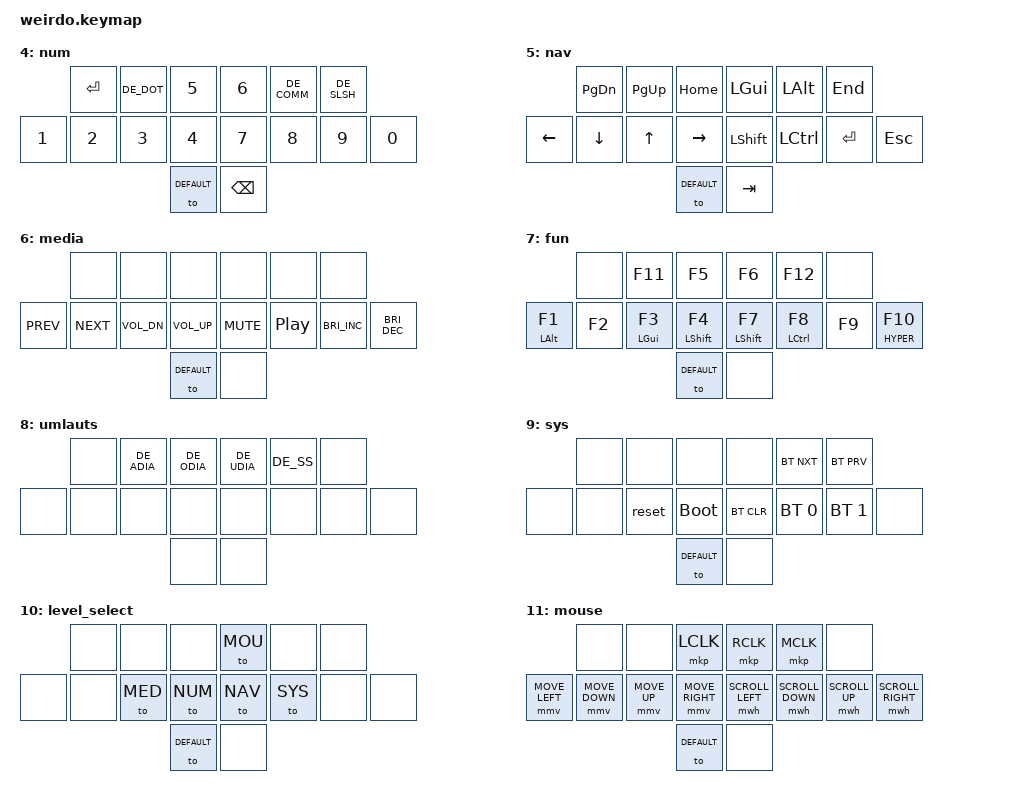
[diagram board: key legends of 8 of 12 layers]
/*
 * Copyright (c) 2021 The ZMK Contributors
 *
 * SPDX-License-Identifier: MIT
 */

#include <behaviors.dtsi>
#include <dt-bindings/zmk/keys.h>
#include <dt-bindings/zmk/bt.h>
#include <dt-bindings/zmk/ext_power.h>
#include <dt-bindings/zmk/mouse.h>

/* GERMAN KEY CODES */
#define DE_CIRC GRAVE // ^ (dead)
#define DE_SS   MINUS // ß
#define DE_ACUT EQUAL // ´ (dead)
#define DE_Q    Q            // Q
#define DE_W    W            // W
#define DE_E    E            // E
#define DE_R    R            // R
#define DE_T    T            // T
#define DE_Z    Y            // Z
#define DE_U    U            // U
#define DE_I    I            // I
#define DE_O    O            // O
#define DE_P    P            // P
#define DE_UDIA LEFT_BRACKET // Ü
#define DE_PLUS RIGHT_BRACKET // +
#define DE_A    A            // A
#define DE_S    S            // S
#define DE_D    D            // D
#define DE_F    F            // F
#define DE_G    G            // G
#define DE_H    H            // H
#define DE_J    J            // J
#define DE_K    K            // K
#define DE_L    L            // L
#define DE_ODIA SEMICOLON    // Ö
#define DE_ADIA SINGLE_QUOTE // Ä
#define DE_HASH NON_US_HASH  // #
#define DE_LABK NON_US_BACKSLASH // <
#define DE_Y    Z                // Y
#define DE_X    X                // X
#define DE_C    C                // C
#define DE_V    V                // V
#define DE_B    B                // B
#define DE_N    N                // N
#define DE_M    M                // M
#define DE_COMM COMMA            // ,
#define DE_DOT  PERIOD           // .
#define DE_MINS SLASH            // -
#define DE_DEG  LS(DE_CIRC) // °
#define DE_EXLM LS(NUMBER_1)    // !
#define DE_DQUO LS(NUMBER_2)    // "
#define DE_SECT LS(NUMBER_3)    // §
#define DE_DLR  LS(NUMBER_4)    // $
#define DE_PERC LS(NUMBER_5)    // %
#define DE_AMPR LS(NUMBER_6)    // &
#define DE_SLSH LS(NUMBER_7)    // /
#define DE_LPRN LS(NUMBER_8)    // (
#define DE_RPRN LS(NUMBER_9)    // )
#define DE_EQL  LS(NUMBER_0)    // =
#define DE_QUES LS(DE_SS)   // ?
#define DE_GRV  LS(DE_ACUT) // ` (dead)
#define DE_ASTR LS(DE_PLUS) // *
#define DE_QUOT LS(DE_HASH) // '
#define DE_RABK LS(DE_LABK) // >
#define DE_SCLN LS(DE_COMM) // ;
#define DE_COLN LS(DE_DOT)  // :
#define DE_UNDS LS(DE_MINS) // _
#define DE_LBRC LA(NUMBER_5)    // [
#define DE_RBRC LA(NUMBER_6)    // ]
#define DE_PIPE LA(NUMBER_7)    // |
#define DE_LCBR LA(NUMBER_8)    // {
#define DE_RCBR LA(NUMBER_9)    // }
#define DE_AT LA(DE_L)    // @
#define DE_EURO LA(DE_E)    // €
#define DE_TILD LA(DE_N)    // ~
#define DE_BSLS LS(LA(NUMBER_7))    // (backslash)

#define DEFAULT 0
#define ALPHA_1 DEFAULT
#define ALPHA_2 1
#define SY1 2
#define SY2 3
#define NUM 4
#define NAV 5
#define MED 6
#define FUN 7
#define UML 8
#define SYS 9
#define LVL 10
#define MOU 11
                                     
#define HOLD_TAP_TIME 200
#define _____ &none
#define HYPER LC(LG(LS(LALT)))

/ {
    conditional_layers {
        compatible = "zmk,conditional-layers";
        tri_layer {
            if-layers = <SY1 SY2>;
            then-layer = <LVL>;
        };
    };
};

&mt {
  tapping-term-ms = <HOLD_TAP_TIME>;
  flavor = "tap-preferred";
  quick_tap_ms = <50>;
};

&lt {
  tapping-term-ms = <HOLD_TAP_TIME>;
  quick_tap_ms = <0>;
  flavor = "tap-preferred";
};

#define DEFAULT_LAYER( K1,  K2,  K3,  K4,  K5,  K6,  K7,  K8, K9,  K10, K11, K12, K13, K14, K15, K16 ) \
                &lt UML K1  &lt NUM K2  &lt NAV K3    &lt NAV K4    &lt NUM K5    &lt UML K6 \
  &hk LALT K7   &lt SY1 K8  &hk LGUI K9 &hk LSHFT K10 &hk LSHFT K11 &hk LCTRL K12 &lt SY2 K13 &hk HYPER K14 \
                                                                K15 K16

/ {
  behaviors {
    hk: hk {
      compatible = "zmk,behavior-hold-tap";
      label = "hk";
      #binding-cells = <2>;
      flavor = "tap-preferred";
      tapping-term-ms = <HOLD_TAP_TIME>;
      quick-tap-ms = <50>;
      bindings = <&sk>, <&kp>;
    };
  };

  keymap {
    compatible = "zmk,keymap";

    // This is a sample keymap intended to be replaced with your own
    alpha_1 {
      bindings = <
        DEFAULT_LAYER(
                DE_L, DE_U, DE_A,       DE_B, DE_D, DE_G, 
          DE_C, DE_R, DE_I, DE_E,       DE_N, DE_T, DE_S, DE_H,
                            &kp SPACE,  &mo ALPHA_2
        )
      >;
    };

    alpha_2 {
      bindings = <
        DEFAULT_LAYER(
                DE_DOT, DE_COMM,  DE_J,          DE_W, DE_Y, DE_Q, 
          DE_V, DE_X,   DE_Z,     DE_O,          DE_M, DE_P, DE_F, DE_K,
                                  &kp BACKSPACE, _____
        )
      >;
    };

    sym_1 {
            bindings = <
                DEFAULT_LAYER(
                    DE_LABK, DE_LBRC, DE_LCBR,      DE_LPRN,     DE_RPRN, DE_RCBR, DE_RBRC, DE_RABK, 
                              DE_SCLN, DE_DQUO,     DE_QUOT,     DE_EXLM, DE_QUES, DE_COLN,     
                                                 &kp DE_DLR, &kp DE_MINS
                )
            >;
        };

    sym_2 {
      bindings = <
           DEFAULT_LAYER(
                             DE_TILD, DE_PIPE,     DE_HASH,     DE_ACUT, DE_DEG,  DE_CIRC,
                    DE_EURO, DE_BSLS, DE_SLSH,     DE_ASTR,     DE_PERC, DE_AMPR, DE_EQL,  DE_GRV, 
                                               &kp DE_UNDS, &kp DE_PLUS           
                )
        >;
    };

    num {
      bindings = <
                &kp ENTER &kp DE_DOT  &kp N5      &kp N6        &kp DE_COMM &kp DE_SLSH
        &kp N1  &kp  N2   &kp N3      &kp N4      &kp N7        &kp N8      &kp N9      &kp N0
                                      &to DEFAULT &kp BACKSPACE
      >;
    };

    nav {
      bindings = <
                  &kp PG_DN &kp PG_UP &kp HOME    &kp LGUI  &kp LALT  &kp END
        &kp LEFT  &kp DOWN  &kp UP    &kp RIGHT   &kp LSHFT &kp LCTRL &kp ENTER &kp ESCAPE
                                      &to DEFAULT &kp TAB
      >;
    };

    media {
      bindings = <
                        _____       _____         _____         _____       _____             _____
            &kp C_PREV  &kp C_NEXT  &kp C_VOL_DN  &kp C_VOL_UP  &kp C_MUTE  &kp C_PLAY_PAUSE  &kp C_BRIGHTNESS_INC &kp C_BRIGHTNESS_DEC
                                                  &to DEFAULT   _____
      >;
    };


    fun {
      bindings = <
                    _____   &kp F11     &kp F5        &kp F6        &kp F12        _____    
        &mt LALT F1 &kp F2  &mt LGUI F3 &mt LSHFT F4  &mt LSHFT F7  &mt LCTRL F8    &kp F9  &mt HYPER F10
                                        &to DEFAULT   _____
      >;
    };

    umlauts {
      bindings = <
              _____ &kp DE_ADIA &kp DE_ODIA &kp DE_UDIA &kp DE_SS _____ 
        _____ _____ _____       _____       _____       _____     _____ _____
                                            _____       _____
      >;
    };

    sys {
        bindings = <
                _____ _____   _____       _____       &bt BT_NXT   &bt BT_PRV
          _____ _____ &reset  &bootloader &bt BT_CLR  &bt BT_SEL 0 &bt BT_SEL 1 _____
                                          &to DEFAULT _____
        >;
    };

    level_select {
      bindings = <
              _____ _____   _____       &to MOU _____   _____
        _____ _____ &to MED &to NUM     &to NAV &to SYS _____ _____
                            &to DEFAULT _____
      >;
    };

    mouse {
      bindings = <
                       _____          _____        &mkp LCLK       &mkp RCLK        &mkp MCLK        _____
        &mmv MOVE_LEFT &mmv MOVE_DOWN &mmv MOVE_UP &mmv MOVE_RIGHT &mwh SCROLL_LEFT &mwh SCROLL_DOWN &mwh SCROLL_UP &mwh SCROLL_RIGHT
                                                   &to DEFAULT     _____
      >;
    };

  };
};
